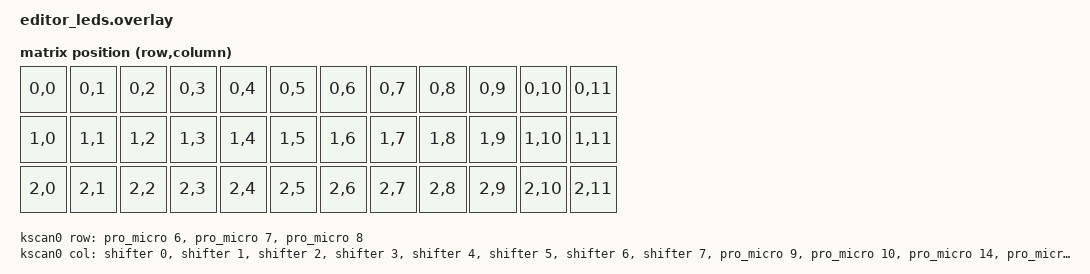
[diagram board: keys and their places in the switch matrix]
/* Generated by ZMK Editor from editor_leds.editor.json. */

#include <dt-bindings/zmk/matrix_transform.h>
#include <physical_layouts.dtsi>
#include <dt-bindings/led/led.h>

/ {
    chosen {
        zmk,kscan = &kscan0;
        zmk,physical-layout = &editor_leds_layout;
    };

    kscan0: kscan {
        compatible = "zmk,kscan-gpio-matrix";
        wakeup-source;
        diode-direction = "col2row";

        row-gpios
            = <&pro_micro  6 (GPIO_ACTIVE_HIGH | GPIO_PULL_DOWN)>
            , <&pro_micro  7 (GPIO_ACTIVE_HIGH | GPIO_PULL_DOWN)>
            , <&pro_micro  8 (GPIO_ACTIVE_HIGH | GPIO_PULL_DOWN)>
            ;

        col-gpios
            = <&shifter  0 GPIO_ACTIVE_HIGH>
            , <&shifter  1 GPIO_ACTIVE_HIGH>
            , <&shifter  2 GPIO_ACTIVE_HIGH>
            , <&shifter  3 GPIO_ACTIVE_HIGH>
            , <&shifter  4 GPIO_ACTIVE_HIGH>
            , <&shifter  5 GPIO_ACTIVE_HIGH>
            , <&shifter  6 GPIO_ACTIVE_HIGH>
            , <&shifter  7 GPIO_ACTIVE_HIGH>
            , <&pro_micro  9 GPIO_ACTIVE_HIGH>
            , <&pro_micro 10 GPIO_ACTIVE_HIGH>
            , <&pro_micro 14 GPIO_ACTIVE_HIGH>
            , <&pro_micro 15 GPIO_ACTIVE_HIGH>
            ;
    };

    default_transform: keymap_transform_0 {
        compatible = "zmk,matrix-transform";
        rows = <3>;
        columns = <12>;
        map = <
RC(0,0)  RC(0,1)  RC(0,2)  RC(0,3)  RC(0,4)  RC(0,5)  RC(0,6)  RC(0,7)  RC(0,8)  RC(0,9)  RC(0,10) RC(0,11)
RC(1,0)  RC(1,1)  RC(1,2)  RC(1,3)  RC(1,4)  RC(1,5)  RC(1,6)  RC(1,7)  RC(1,8)  RC(1,9)  RC(1,10) RC(1,11)
RC(2,0)  RC(2,1)  RC(2,2)  RC(2,3)  RC(2,4)  RC(2,5)  RC(2,6)  RC(2,7)  RC(2,8)  RC(2,9)  RC(2,10) RC(2,11)
        >;
    };

    editor_leds_layout: editor_leds_layout {
        compatible = "zmk,physical-layout";
        display-name = "LED Pad";
        transform = <&default_transform>;

        keys  //                     w   h    x    y     rot   rx   ry
            = <&key_physical_attrs 100 100    0    0      0    0    0>
            , <&key_physical_attrs 100 100  100    0      0    0    0>
            , <&key_physical_attrs 100 100  200    0      0    0    0>
            , <&key_physical_attrs 100 100  300    0      0    0    0>
            , <&key_physical_attrs 100 100  400    0      0    0    0>
            , <&key_physical_attrs 100 100  500    0      0    0    0>
            , <&key_physical_attrs 100 100  600    0      0    0    0>
            , <&key_physical_attrs 100 100  700    0      0    0    0>
            , <&key_physical_attrs 100 100  800    0      0    0    0>
            , <&key_physical_attrs 100 100  900    0      0    0    0>
            , <&key_physical_attrs 100 100 1000    0      0    0    0>
            , <&key_physical_attrs 100 100 1100    0      0    0    0>
            , <&key_physical_attrs 100 100    0  100      0    0    0>
            , <&key_physical_attrs 100 100  100  100      0    0    0>
            , <&key_physical_attrs 100 100  200  100      0    0    0>
            , <&key_physical_attrs 100 100  300  100      0    0    0>
            , <&key_physical_attrs 100 100  400  100      0    0    0>
            , <&key_physical_attrs 100 100  500  100      0    0    0>
            , <&key_physical_attrs 100 100  600  100      0    0    0>
            , <&key_physical_attrs 100 100  700  100      0    0    0>
            , <&key_physical_attrs 100 100  800  100      0    0    0>
            , <&key_physical_attrs 100 100  900  100      0    0    0>
            , <&key_physical_attrs 100 100 1000  100      0    0    0>
            , <&key_physical_attrs 100 100 1100  100      0    0    0>
            , <&key_physical_attrs 100 100    0  200      0    0    0>
            , <&key_physical_attrs 100 100  100  200      0    0    0>
            , <&key_physical_attrs 100 100  200  200      0    0    0>
            , <&key_physical_attrs 100 100  300  200      0    0    0>
            , <&key_physical_attrs 100 100  400  200      0    0    0>
            , <&key_physical_attrs 100 100  500  200      0    0    0>
            , <&key_physical_attrs 100 100  600  200      0    0    0>
            , <&key_physical_attrs 100 100  700  200      0    0    0>
            , <&key_physical_attrs 100 100  800  200      0    0    0>
            , <&key_physical_attrs 100 100  900  200      0    0    0>
            , <&key_physical_attrs 100 100 1000  200      0    0    0>
            , <&key_physical_attrs 100 100 1100  200      0    0    0>
            ;
    };
};

&pinctrl {
    nice_view_spi_default: nice_view_spi_default {
        group1 {
            psels = <NRF_PSEL(SPIM_SCK, 0, 20)>,
                <NRF_PSEL(SPIM_MOSI, 0, 17)>;
        };
    };
    nice_view_spi_sleep: nice_view_spi_sleep {
        group1 {
            psels = <NRF_PSEL(SPIM_SCK, 0, 20)>,
                <NRF_PSEL(SPIM_MOSI, 0, 17)>;
            low-power-enable;
        };
    };
};

nice_view_spi: &pro_micro_spi {
    status = "okay";
    compatible = "nordic,nrf-spim";
    pinctrl-0 = <&nice_view_spi_default>;
    pinctrl-1 = <&nice_view_spi_sleep>;
    pinctrl-names = "default", "sleep";
    cs-gpios = <&pro_micro 1 GPIO_ACTIVE_HIGH>, <&pro_micro 21 GPIO_ACTIVE_LOW>;

    shifter: 595@1 {
        compatible = "zmk,gpio-595";
        status = "okay";
        gpio-controller;
        spi-max-frequency = <1000000>;
        reg = <1>;
        #gpio-cells = <2>;
        ngpios = <8>;
    };
};

&pro_micro_i2c {
    status = "disabled";
};

/ {
    chosen {
        zmk,underglow = &led_strip;
    };
};

&pinctrl {
    led_spi_default: led_spi_default {
        group1 {
            psels = <NRF_PSEL(SPIM_MOSI, 0, 22)>;
        };
    };
    led_spi_sleep: led_spi_sleep {
        group1 {
            psels = <NRF_PSEL(SPIM_MOSI, 0, 22)>;
            low-power-enable;
        };
    };
};

&spi3 {
    status = "okay";
    compatible = "nordic,nrf-spim";
    pinctrl-0 = <&led_spi_default>;
    pinctrl-1 = <&led_spi_sleep>;
    pinctrl-names = "default", "sleep";

    led_strip: ws2812@0 {
        compatible = "worldsemi,ws2812-spi";
        reg = <0>;
        spi-max-frequency = <4000000>;
        chain-length = <20>;
        spi-one-frame = <0x70>;
        spi-zero-frame = <0x40>;
        color-mapping = <LED_COLOR_ID_GREEN LED_COLOR_ID_RED LED_COLOR_ID_BLUE>;
    };
};

/* ZMK's external power switches the LEDs' power; the board's own 3.3V pin stays on. */
&{/EXT_POWER} {
    control-gpios = <&pro_micro 5 GPIO_ACTIVE_HIGH>;
};

&gpio0 {
    vcc_always_on {
        gpio-hog;
        gpios = <13 GPIO_ACTIVE_HIGH>;
        output-high;
    };
};
